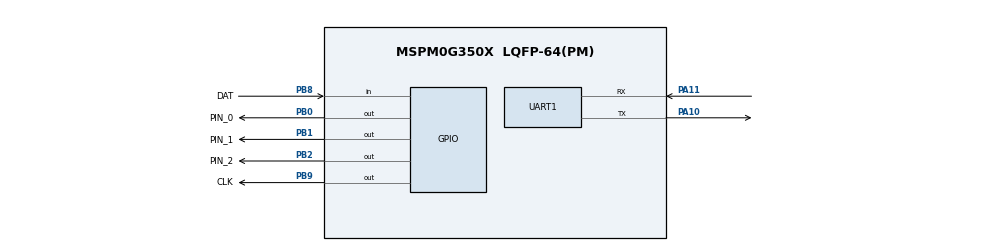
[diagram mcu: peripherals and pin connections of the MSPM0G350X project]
/**
 * @cliArgs --device "MSPM0G350X" --package "LQFP-64(PM)" --part "Default" --product "mspm0_sdk@1.30.00.03"
 * @versions {"tool":"1.19.0+3426"}
 */

/**
 * Import the modules used in this configuration.
 */
const ADC12   = scripting.addModule("/ti/driverlib/ADC12", {}, false);
const ADC121  = ADC12.addInstance();
const GPIO    = scripting.addModule("/ti/driverlib/GPIO", {}, false);
const GPIO1   = GPIO.addInstance();
const GPIO2   = GPIO.addInstance();
const GPIO3   = GPIO.addInstance();
const SYSCTL  = scripting.addModule("/ti/driverlib/SYSCTL");
const SYSTICK = scripting.addModule("/ti/driverlib/SYSTICK");
const UART    = scripting.addModule("/ti/driverlib/UART", {}, false);
const UART1   = UART.addInstance();

/**
 * Write custom configuration values to the imported modules.
 */
const divider2       = system.clockTree["HFCLK4MFPCLKDIV"];
divider2.divideValue = 6;

const divider6       = system.clockTree["PLL_CLK2X_DIV"];
divider6.divideValue = 1;

const gate7  = system.clockTree["MFCLKGATE"];
gate7.enable = true;

const gate8  = system.clockTree["MFPCLKGATE"];
gate8.enable = true;

const multiplier2         = system.clockTree["PLL_QDIV"];
multiplier2.multiplyValue = 4;

const pinFunction3     = system.clockTree["HFCLKEXT"];
pinFunction3.inputFreq = 40;

const pinFunction4     = system.clockTree["HFXT"];
pinFunction4.inputFreq = 40;
pinFunction4.enable    = true;

ADC121.sampClkDiv                        = "DL_ADC12_CLOCK_DIVIDE_8";
ADC121.repeatMode                        = true;
ADC121.adcMem0_name                      = "ADC_Channel0";
ADC121.endAdd                            = 11;
ADC121.$name                             = "ADC1";
ADC121.powerDownMode                     = "DL_ADC12_POWER_DOWN_MODE_MANUAL";
ADC121.sampleTime0                       = "0. ms";
ADC121.adcPin0Config.hideOutputInversion = scripting.forceWrite(false);
ADC121.adcPin0Config.$name               = "ti_driverlib_gpio_GPIOPinGeneric4";

const Board = scripting.addModule("/ti/driverlib/Board", {}, false);

GPIO1.$name                              = "LED";
GPIO1.port                               = "PORTB";
GPIO1.associatedPins[0].internalResistor = "PULL_DOWN";
GPIO1.associatedPins[0].$name            = "PIN_22";
GPIO1.associatedPins[0].assignedPin      = "22";

GPIO2.$name                         = "Gray_Address";
GPIO2.associatedPins.create(3);
GPIO2.associatedPins[0].$name       = "PIN_0";
GPIO2.associatedPins[0].pin.$assign = "PB0";
GPIO2.associatedPins[1].$name       = "PIN_1";
GPIO2.associatedPins[1].pin.$assign = "PB1";
GPIO2.associatedPins[2].$name       = "PIN_2";
GPIO2.associatedPins[2].pin.$assign = "PB2";

GPIO3.$name                         = "Serial";
GPIO3.associatedPins.create(2);
GPIO3.associatedPins[0].$name       = "DAT";
GPIO3.associatedPins[0].direction   = "INPUT";
GPIO3.associatedPins[0].pin.$assign = "PB8";
GPIO3.associatedPins[1].$name       = "CLK";
GPIO3.associatedPins[1].pin.$assign = "PB9";

SYSCTL.forceDefaultClkConfig = true;
SYSCTL.clockTreeEn           = true;

SYSTICK.periodEnable  = true;
SYSTICK.systickEnable = true;
SYSTICK.period        = 80;

UART1.$name                    = "UART_0";
UART1.uartClkDiv               = "2";
UART1.targetBaudRate           = 115200;
UART1.peripheral.rxPin.$assign = "PA11";
UART1.peripheral.txPin.$assign = "PA10";
UART1.txPinConfig.$name        = "ti_driverlib_gpio_GPIOPinGeneric0";
UART1.rxPinConfig.$name        = "ti_driverlib_gpio_GPIOPinGeneric1";

/**
 * Pinmux solution for unlocked pins/peripherals. This ensures that minor changes to the automatic solver in a future
 * version of the tool will not impact the pinmux you originally saw.  These lines can be completely deleted in order to
 * re-solve from scratch.
 */
pinFunction4.peripheral.$suggestSolution           = "SYSCTL";
pinFunction4.peripheral.hfxInPin.$suggestSolution  = "PA5";
pinFunction4.peripheral.hfxOutPin.$suggestSolution = "PA6";
ADC121.peripheral.$suggestSolution                 = "ADC0";
ADC121.peripheral.adcPin0.$suggestSolution         = "PA27";
Board.peripheral.$suggestSolution                  = "DEBUGSS";
Board.peripheral.swclkPin.$suggestSolution         = "PA20";
Board.peripheral.swdioPin.$suggestSolution         = "PA19";
GPIO1.associatedPins[0].pin.$suggestSolution       = "PB22";
UART1.peripheral.$suggestSolution                  = "UART0";
